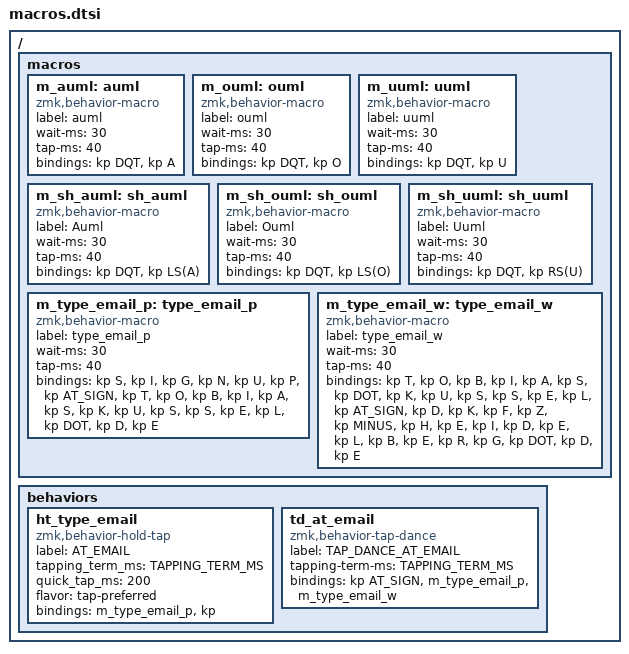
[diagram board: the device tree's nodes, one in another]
// Make sure settings.dtsi is included before this file

/*
 * Type Personal Email Macro
 *
 * Usage:
 *   - &m_type_email_p - Send macro
 *   - &ht_type_email 0 AT_SIGN - Send macro on hold / Send @ on tap
 *  -  &td_at_email - Send at on tap, personal email on double tap and work email on tripple tap
 */
/ {
    macros {
	m_auml: auml {
            compatible = "zmk,behavior-macro";
            label = "auml";
            #binding-cells = <0>;
            wait-ms = <30>;
            tap-ms = <40>;
            bindings = <
                &kp DQT &kp A
            >;
        };
	m_ouml: ouml {
            compatible = "zmk,behavior-macro";
            label = "ouml";
            #binding-cells = <0>;
            wait-ms = <30>;
            tap-ms = <40>;
            bindings = <
                &kp DQT &kp O
            >;
        };
	m_uuml: uuml {
            compatible = "zmk,behavior-macro";
            label = "uuml";
            #binding-cells = <0>;
            wait-ms = <30>;
            tap-ms = <40>;
            bindings = <
                &kp DQT &kp U
            >;
        };
	m_sh_auml: sh_auml {
            compatible = "zmk,behavior-macro";
            label = "Auml";
            #binding-cells = <0>;
            wait-ms = <30>;
            tap-ms = <40>;
            bindings = <
                &kp DQT &kp LS(A)
            >;
        };
	m_sh_ouml: sh_ouml {
            compatible = "zmk,behavior-macro";
            label = "Ouml";
            #binding-cells = <0>;
            wait-ms = <30>;
            tap-ms = <40>;
            bindings = <
                &kp DQT &kp LS(O)
            >;
        };
	m_sh_uuml: sh_uuml {
            compatible = "zmk,behavior-macro";
            label = "Uuml";
            #binding-cells = <0>;
            wait-ms = <30>;
            tap-ms = <40>;
            bindings = <
                &kp DQT &kp RS(U)
            >;
        };

        m_type_email_p: type_email_p {
            compatible = "zmk,behavior-macro";
            label = "type_email_p";
            #binding-cells = <0>;
            wait-ms = <30>;
            tap-ms = <40>;
            bindings = <
                &kp S &kp I &kp G &kp N &kp U &kp P
                &kp AT_SIGN
                &kp T &kp O &kp B &kp I &kp A &kp S &kp K &kp U &kp S &kp S &kp E &kp L
                &kp DOT
                &kp D &kp E
            >;
        };

        m_type_email_w: type_email_w {
            compatible = "zmk,behavior-macro";
            label = "type_email_w";
            #binding-cells = <0>;
            wait-ms = <30>;
            tap-ms = <40>;
            bindings = <
                &kp T &kp O &kp B &kp I &kp A &kp S
                &kp DOT
                &kp K &kp U &kp S &kp S &kp E &kp L
                &kp AT_SIGN
                &kp D &kp K &kp F &kp Z &kp MINUS &kp H &kp E &kp I &kp D &kp E &kp L &kp B &kp E &kp R &kp G
                &kp DOT
                &kp D &kp E
            >;
        };

    };


    behaviors {

        ht_type_email: ht_type_email {
            compatible = "zmk,behavior-hold-tap";
            label = "AT_EMAIL";
            #binding-cells = <2>;
            tapping_term_ms = <TAPPING_TERM_MS>;
            quick_tap_ms = <200>;
            flavor = "tap-preferred";
            bindings = <&m_type_email_p>, <&kp>;
        };

        td_at_email: td_at_email {
            compatible = "zmk,behavior-tap-dance";
            label = "TAP_DANCE_AT_EMAIL";
            #binding-cells = <0>;
            tapping-term-ms = <TAPPING_TERM_MS>;
            bindings = <&kp AT_SIGN>, <&m_type_email_p>, <&m_type_email_w>;
        };

    };
};
